# earlgrey register map
Vendor: lowRISC; File version: 0.1
CPU: ibex rev01, little endian, no MPU, no FPU, VTOR, 2 interrupt priority bits, 2 interrupts
Registers are 32-bit, read-write, no defined reset value unless marked. A register's access mark holds for its fields unless they carry their own. Offsets are from the block's base; [hi:lo] are bit positions; {n}, {i} and the like mark numbered series.

## AON_TIMER_AON — Wakeup and watchdog timers running on a low-power, always-on clock
Base 0x40470000
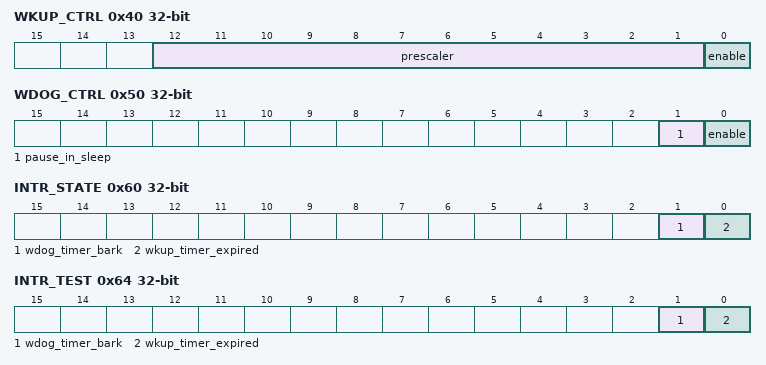
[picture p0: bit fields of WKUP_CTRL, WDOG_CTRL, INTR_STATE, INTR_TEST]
0x40 WKUP_CTRL — Wakeup Timer Control register
  [12:1] prescaler — Pre-scaler value for wakeup timer count
  [0] enable — When set to 1, the wakeup timer will count
0x44 WKUP_THOLD — Wakeup Timer Threshold Register
  [31:0] threshold — The count at which a wakeup interrupt should be generated
0x48 WKUP_COUNT — Wakeup Timer Count Register
  [31:0] count — The current wakeup counter value
0x4C WDOG_REGWEN — Watchdog Timer Write Enable Register
  [0] regwen — Once cleared, the watchdog configuration will be locked until the next reset
0x50 WDOG_CTRL — Watchdog Timer Control register
  [1] pause_in_sleep — When set to 1, the watchdog timer will not count during sleep
  [0] enable — When set to 1, the watchdog timer will count
0x54 WDOG_BARK_THOLD — Watchdog Timer Bark Threshold Register
  [31:0] threshold — The count at which a watchdog bark interrupt should be generated
0x58 WDOG_BITE_THOLD — Watchdog Timer Bite Threshold Register
  [31:0] threshold — The count at which a watchdog bite reset should be generated
0x5C WDOG_COUNT — Watchdog Timer Count Register
  [31:0] count — The current watchdog counter value
0x60 INTR_STATE — Interrupt State Register
  [1] wdog_timer_bark — Raised if the watchdog timer has hit the bark threshold
  [0] wkup_timer_expired — Raised if the wakeup timer has hit the specified threshold
0x64 INTR_TEST wo — Interrupt Test Register
  [1] wdog_timer_bark — Write 1 to force wdog_timer_bark interrupt
  [0] wkup_timer_expired — Write 1 to force wkup_timer_expired interrupt
0x68 WKUP_CAUSE — Wakeup request status
  [0] cause — AON timer requested wakeup, write 0 to clear

## AST
Base 0x40480000
0x40 REGA0 ro — AST Register 0 for OTP/ROM Write Testing
  [31:0] reg32 — 32-bit Register
0x44 REGA1 ro — AST 1 Register for OTP/ROM Write Testing
  [31:0] reg32 — 32-bit Register
{0x40+4i} REGA{i} (i=2..11) — AST {i} Register for OTP/ROM Write Testing
  [31:0] reg32 — 32-bit Register
0x70 REGA12 — AST 13 Register for OTP/ROM Write Testing
  [31:0] reg32 — 32-bit Register
{0x40+4i} REGA{i} (i=13..27) — AST {i} Register for OTP/ROM Write Testing
  [31:0] reg32 — 32-bit Register
0xB0 REGA28 ro — AST 28 Register for OTP/ROM Write Testing
  [31:0] reg32 — 32-bit Register
{0x40+4i} REGA{i} (i=29..37) — AST {i} Register for OTP/ROM Write Testing
  [31:0] reg32 — 32-bit Register
0xD8 REGAL wo — AST Last Register for OTP/ROM Write Testing
  [31:0] reg32 — 32-bit Register
{0x200+4i} REGB_{i} (i=0..4) — AST Registers Array-B to set address space size
  [31:0] reg32_{i} — 32-bit Register

## SENSOR_CTRL_AON
Base 0x40490000
0x40 CFG_REGWEN — Controls the configurability of !!FATAL_ALERT_EN register.
  [0] EN — Configuration enable.
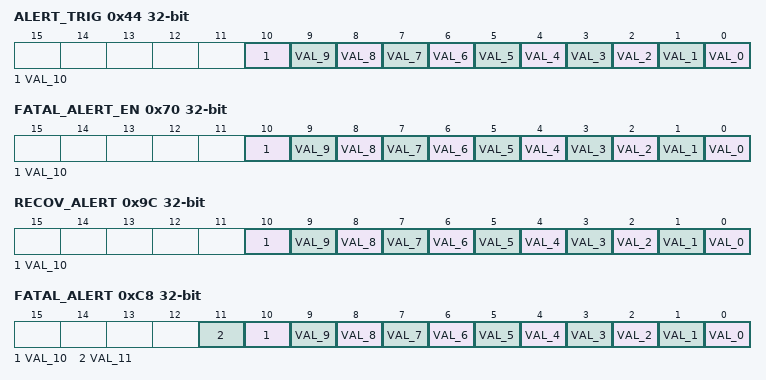
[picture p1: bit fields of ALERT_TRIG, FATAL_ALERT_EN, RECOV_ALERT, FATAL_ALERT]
0x44 ALERT_TRIG — Alert trigger test
  [n] VAL_{n} (n=0..10) — Alert trigger for testing0 No alerts triggered1 Continuously trigger alert until disabledFor bit mapping, please see !!ALERT_TEST
0x70 FATAL_ALERT_EN — Each bit marks a corresponding alert as fatal or recoverable.
  [n] VAL_{n} (n=0..10) — 1 - An alert event is fatal.0 - An alert event is recoverable.
0x9C RECOV_ALERT — Each bit represents a recoverable alert that has been triggered by AST.Since these are recoverable alerts, they can be cleared by software.
  [n] VAL_{n} (n=0..10) — 1 - An alert event has been set0 - No alert event has been set
0xC8 FATAL_ALERT ro — Each bit represents a fatal alert that has been triggered by AST.Since these registers represent fatal alerts, they cannot be cleared.The lower bits are used for ast alert events.The upper bits are used for local events.
  [n] VAL_{n} (n=0..11) — 1 - An alert event has been set0 - No alert event has been set
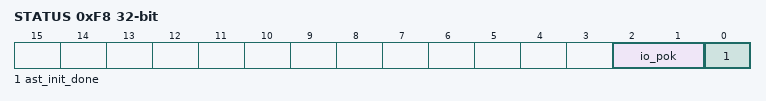
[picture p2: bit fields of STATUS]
0xF8 STATUS ro — Status readback for ast
  [2:1] io_pok — IO power is ready
  [0] ast_init_done — AST has finished initializing
